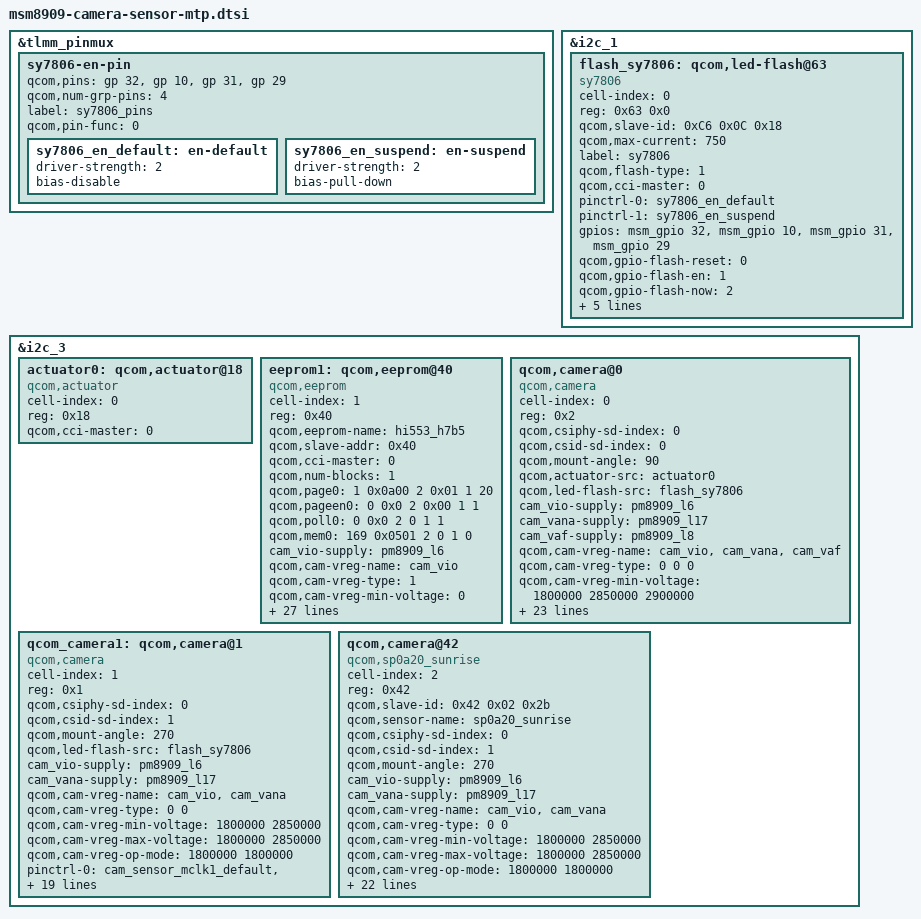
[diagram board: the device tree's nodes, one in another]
/*
 * Copyright (c) 2014-2015, The Linux Foundation. All rights reserved.
 *
 * This program is free software; you can redistribute it and/or modify
 * it under the terms of the GNU General Public License version 2 and
 * only version 2 as published by the Free Software Foundation.
 *
 * This program is distributed in the hope that it will be useful,
 * but WITHOUT ANY WARRANTY; without even the implied warranty of
 * MERCHANTABILITY or FITNESS FOR A PARTICULAR PURPOSE.  See the
 * GNU General Public License for more details.
 */

//Begin add by zhaohong.chen@tcl.com for POP45 flashlight driver, 20151218
&tlmm_pinmux {	
	sy7806-en-pin {
		qcom,pins = <&gp 32>, <&gp 10>, <&gp 31>, <&gp 29>;
		qcom,num-grp-pins = <4>;
		label = "sy7806_pins";
		qcom,pin-func = <0>;

		sy7806_en_default: en-default {
			driver-strength = <2>;
			bias-disable;
		};
		sy7806_en_suspend: en-suspend {
			driver-strength = <2>;
			bias-pull-down;
		};
	};
};

&i2c_1 {
	flash_sy7806:qcom,led-flash@63 { //if set 0xc6 here, can not probe
		cell-index = <0>;
		reg = <0x63 0x0>;
		qcom,slave-id = <0xC6 0x0C 0x18>; //0xc6 >> 1 ,  real i2c addr
		compatible = "sy7806";
		qcom,max-current = <750>; //determine current & the number of torch source
		label = "sy7806";
		qcom,flash-type = <1>;
		qcom,cci-master = <0>;
		pinctrl-names = "cam_flash_default","cam_flash_suspend";
		pinctrl-0 = <&sy7806_en_default>;
		pinctrl-1 = <&sy7806_en_suspend>;
		gpios = <&msm_gpio 32 0>,  //hwen: control i2c, output & reset regs
				<&msm_gpio 10 0>,  //strobe
				<&msm_gpio 31 0>,  //torch
				<&msm_gpio 29 0>;  //tx
		qcom,gpio-flash-reset = <0>;
		qcom,gpio-flash-en = <1>;
		qcom,gpio-flash-now = <2>;
		qcom,gpio-custom1 = <3>;
		qcom,gpio-req-tbl-num = <0 1 2 3>;
		qcom,gpio-req-tbl-flags = <0 0 0 0>;
		qcom,gpio-req-tbl-label = "FLASH_RST",
								  "FLASH_EN",
					  			  "FLASH_NOW",
								  "FLASH_TX";
	};
};
//End add

&i2c_3 {
	actuator0: qcom,actuator@18 {
		cell-index = <0>;
		reg = <0x18>;
		compatible = "qcom,actuator";
		qcom,cci-master = <0>;
	};
         //add by jin.xia@tcl.com for eeprom 2016-2-23

    	eeprom1: qcom,eeprom@40 {
	   cell-index = <1>;
	   reg = <0x40>;
	   qcom,eeprom-name = "hi553_h7b5";
	   compatible = "qcom,eeprom";
	   qcom,slave-addr = <0x40>;
	   qcom,cci-master = <0>;
	   qcom,num-blocks = <1>;



	   qcom,page0 = <1 0x0a00 2 0x01 1 20>;//sensor  sleep read regs
	   qcom,pageen0 = <0 0x0 2 0x00 1 1>;
	   qcom,poll0 = <0 0x0 2 0 1 1>;
	   qcom,mem0 = <169 0x0501 2 0 1 0>;

		cam_vio-supply = <&pm8909_l6>;
		qcom,cam-vreg-name = "cam_vio";
		qcom,cam-vreg-type = <1>;
		qcom,cam-vreg-min-voltage = <0>;
		qcom,cam-vreg-max-voltage = <0>;
		qcom,cam-vreg-op-mode = <0>;
		pinctrl-names = "cam_default", "cam_suspend";
		pinctrl-0 = <&cam_sensor_mclk1_default &cam_sensor_front_default>;
		pinctrl-1 = <&cam_sensor_mclk1_sleep &cam_sensor_front_sleep>;
		gpios = <&msm_gpio 27 0>,
			<&msm_gpio 28 0>,
			<&msm_gpio 33 0>,
			<&msm_gpio 110 0>,
			<&msm_gpio 93 0>;
		qcom,gpio-reset = <1>;
		qcom,gpio-standby = <2>;
		qcom,gpio-vdig = <3>;
		qcom,gpio-vana = <4>;
		qcom,gpio-req-tbl-num = <0 1 2 3 4>;
		qcom,gpio-req-tbl-flags = <1 0 0 0 0>;
		qcom,gpio-req-tbl-label = "CAMIF_MCLK",
			"CAM_RESET",
			"CAM_STANDBY",
			"CAM_VDIG",
			"CAM_VANA";


	   qcom,cam-power-seq-type = "sensor_vreg","sensor_clk","sensor_gpio","sensor_gpio",
		   "sensor_gpio", "sensor_gpio";
		   
	   qcom,cam-power-seq-val = "cam_vio","sensor_cam_mclk","sensor_gpio_reset",
	   	"sensor_gpio_standby","sensor_gpio_vdig",   "sensor_gpio_vana";
		
	   qcom,cam-power-seq-cfg-val = <1 23880000 1 1 1 1>;
	   qcom,cam-power-seq-delay = <5 5 5 5 5 5>;

	   

	   clocks = <&clock_gcc clk_mclk1_clk_src>,
			<&clock_gcc clk_gcc_camss_mclk1_clk>;
	   clock-names = "cam_src_clk", "cam_clk";			
			

	};
//end add
	qcom,camera@0 {
		cell-index = <0>;
		compatible = "qcom,camera";
		reg = <0x2>;
		qcom,csiphy-sd-index = <0>;
		qcom,csid-sd-index = <0>;
		qcom,mount-angle = <90>;
		qcom,actuator-src = <&actuator0>;
		qcom,led-flash-src = <&flash_sy7806>;
		cam_vio-supply = <&pm8909_l6>;
		cam_vana-supply = <&pm8909_l17>;
		cam_vaf-supply = <&pm8909_l8>;
		qcom,cam-vreg-name = "cam_vio","cam_vana","cam_vaf"; 
		qcom,cam-vreg-type = <0 0  0>;
		qcom,cam-vreg-min-voltage = <1800000 2850000 2900000>;
		qcom,cam-vreg-max-voltage = <1800000 2850000 2900000>;
		qcom,cam-vreg-op-mode = <200000 200000 100000>;
		pinctrl-names = "cam_default", "cam_suspend";
		pinctrl-0 = <&cam_sensor_mclk0_default &cam_sensor_rear_default>;
		pinctrl-1 = <&cam_sensor_mclk0_sleep &cam_sensor_rear_sleep>;
		gpios = <&msm_gpio 26 0>,
			    <&msm_gpio 35 0>,
			    <&msm_gpio 34 0>,
			    <&msm_gpio 110 0>,//for dvdd 
			    <&msm_gpio 93 0>;//for avdd mod by jin.xia for compatible power supply 2012-12-23
		qcom,gpio-reset = <1>;
		qcom,gpio-standby = <2>;
		qcom,gpio-vdig = <3>;
		qcom,gpio-vana = <4>;
		qcom,gpio-req-tbl-num = <0 1 2 3 4>;
		qcom,gpio-req-tbl-flags = <1 0 0 0 0>;
		qcom,gpio-req-tbl-label = "CAMIF_MCLK",
		                          "CAM_RESET1",
		                          "CAM_STANDBY",			
                                          "CAM_GPIO_VDIG",
                                          "CAM_GPIO_VANA";			
		qcom,sensor-position = <0>;
		qcom,sensor-mode = <1>;
		qcom,cci-master = <0>;
		status = "ok";
		clocks = <&clock_gcc clk_mclk0_clk_src>,
				<&clock_gcc clk_gcc_camss_mclk0_clk>;
		clock-names = "cam_src_clk", "cam_clk";
	};

	qcom_camera1: qcom,camera@1 {
		cell-index = <1>;
		compatible = "qcom,camera";
		reg = <0x1>;
		qcom,csiphy-sd-index = <0>;
		qcom,csid-sd-index = <1>;
		qcom,mount-angle = <270>;
		qcom,led-flash-src = <&flash_sy7806>;
		cam_vio-supply = <&pm8909_l6>; //dovdd
		cam_vana-supply = <&pm8909_l17>; //avdd
		qcom,cam-vreg-name = "cam_vio","cam_vana";
		qcom,cam-vreg-type = <0 0>;
		qcom,cam-vreg-min-voltage = < 1800000 2850000>;
		qcom,cam-vreg-max-voltage = < 1800000 2850000>;
		qcom,cam-vreg-op-mode = < 1800000 1800000>;
		pinctrl-names = "cam_default", "cam_suspend";
		pinctrl-0 = <&cam_sensor_mclk1_default &cam_sensor_front_default>;
		pinctrl-1 = <&cam_sensor_mclk1_sleep &cam_sensor_front_sleep>;
		gpios = <&msm_gpio 27 0>,
			<&msm_gpio 28 0>,  //reset
			<&msm_gpio 33 0>,  //pwdn
			<&msm_gpio 110 0>, //dvdd
			<&msm_gpio 93 0>;//for avdd mod by jin.xia for compatible power supply 2012-12-23
		qcom,gpio-reset = <1>;
		qcom,gpio-standby = <2>;
		qcom,gpio-vdig = <3>;
		qcom,gpio-vana = <4>;
		qcom,gpio-req-tbl-num = <0 1 2 3 4>;
		qcom,gpio-req-tbl-flags = <1 0 0 0 0>;
		qcom,gpio-req-tbl-label = "CAMIF_MCLK",
		                          "CAM_RESET",
					  "CAM_STANDBY",
					  "CAM_GPIO_VDIG",
					  "CAM_GPIO_VANA";
		qcom,sensor-position = <1>;
		qcom,sensor-mode = <1>;
		qcom,cci-master = <0>;
		status = "ok";
		clocks = <&clock_gcc clk_mclk1_clk_src>,
				<&clock_gcc clk_gcc_camss_mclk1_clk>;
		clock-names = "cam_src_clk", "cam_clk";
	};
	
	qcom,camera@42 {
		cell-index = <2>;
		compatible = "qcom,sp0a20_sunrise";
		reg = <0x42>;
		qcom,slave-id = <0x42 0x02 0x2b>;
		qcom,sensor-name = "sp0a20_sunrise";
		qcom,csiphy-sd-index = <0>;
		qcom,csid-sd-index = <1>;
		qcom,mount-angle = <270>;
		cam_vio-supply = <&pm8909_l6>;
		cam_vana-supply = <&pm8909_l17>;
		qcom,cam-vreg-name = "cam_vio","cam_vana";
		qcom,cam-vreg-type = <0 0>;
		qcom,cam-vreg-min-voltage = < 1800000 2850000>;
		qcom,cam-vreg-max-voltage = < 1800000 2850000>;
		qcom,cam-vreg-op-mode = < 1800000 1800000>;
		pinctrl-names = "cam_default", "cam_suspend";
		pinctrl-0 = <&cam_sensor_mclk1_default &cam_sensor_front_default>;
		pinctrl-1 = <&cam_sensor_mclk1_sleep &cam_sensor_front_sleep>;
		gpios = <&msm_gpio 27 0>,
			<&msm_gpio 28 0>,
			<&msm_gpio 33 0>,
			<&msm_gpio 110 0>,
			<&msm_gpio 93 0>;
		qcom,gpio-reset = <1>;
		qcom,gpio-standby = <2>;
		qcom,gpio-vdig = <3>;
		qcom,gpio-vana = <4>;
		qcom,gpio-req-tbl-num = <0 1 2 3 4>;
		qcom,gpio-req-tbl-flags = <1 0 0 0 0>;
		qcom,gpio-req-tbl-label = "CAMIF_MCLK",
		              "CAM_RESET",
					  "CAM_STANDBY",
					  "CAM_GPIO_VDIG",
					  "CAM_GPIO_VANA";
        qcom,csi-lane-assign = <0x0004>;
        qcom,csi-lane-mask = <0x18>;
		qcom,sensor-position = <1>;
		qcom,sensor-mode = <1>;
		qcom,cci-master = <0>;
		status = "ok";
		clocks = <&clock_gcc clk_mclk1_clk_src>,
				<&clock_gcc clk_gcc_camss_mclk1_clk>;
		clock-names = "cam_src_clk", "cam_clk";
	};
};
